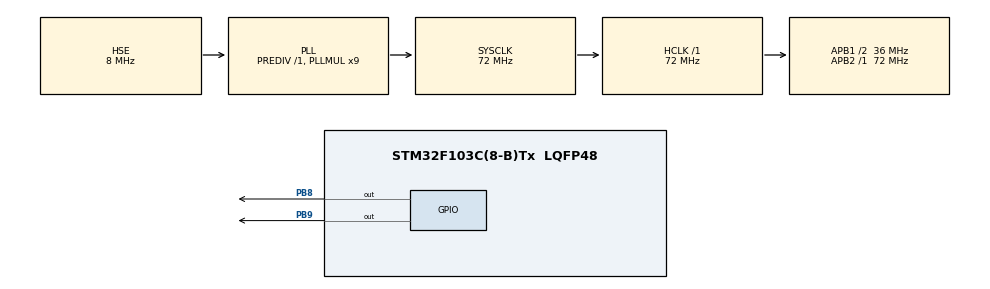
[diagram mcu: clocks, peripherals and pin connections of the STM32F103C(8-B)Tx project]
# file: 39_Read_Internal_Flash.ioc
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Mcu.Family=STM32F1
Mcu.Name=STM32F103C(8-B)Tx
Mcu.Package=LQFP48
NVIC.PriorityGroup=NVIC_PRIORITYGROUP_4
PA13.Mode=Serial_Wire
PA13.Signal=SYS_JTMS-SWDIO
PA14.Mode=Serial_Wire
PA14.Signal=SYS_JTCK-SWCLK
PB8.Signal=GPIO_Output
PB9.Signal=GPIO_Output
PD0-OSC_IN.Mode=HSE-External-Oscillator
PD0-OSC_IN.Signal=RCC_OSC_IN
PD1-OSC_OUT.Mode=HSE-External-Oscillator
PD1-OSC_OUT.Signal=RCC_OSC_OUT
ProjectManager.HeapSize=0x200
ProjectManager.StackSize=0x400
ProjectManager.TargetToolchain=MDK-ARM V5.32
RCC.AHBFreq_Value=72000000
RCC.APB1CLKDivider=RCC_HCLK_DIV2
RCC.APB1Freq_Value=36000000
RCC.APB1TimFreq_Value=72000000
RCC.APB2Freq_Value=72000000
RCC.APB2TimFreq_Value=72000000
RCC.HCLKFreq_Value=72000000
RCC.PLLMUL=RCC_PLL_MUL9
RCC.PLLSourceVirtual=RCC_PLLSOURCE_HSE
RCC.SYSCLKFreq_VALUE=72000000
RCC.SYSCLKSource=RCC_SYSCLKSOURCE_PLLCLK
RCC.USBFreq_Value=72000000
board=custom

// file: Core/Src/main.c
/* USER CODE BEGIN Header */
/**
 ******************************************************************************
 * @file           : main.c
 * @brief          : Main program body
 ******************************************************************************
 * @attention
 *
 * Copyright (c) 2026 STMicroelectronics.
 * All rights reserved.
 *
 * This software is licensed under terms that can be found in the LICENSE file
 * in the root directory of this software component.
 * If no LICENSE file comes with this software, it is provided AS-IS.
 *
 ******************************************************************************
 */
/* USER CODE END Header */
#include "main.h"
#include "gpio.h"

/* USER CODE BEGIN Includes */
#include "OLED.h"
/* USER CODE END Includes */

/* USER CODE BEGIN PV */
/*
  * @brief  FLASH读取一个32位的字(字就是32位)
  * @param  Address: 要读取的地址
  * @retval 指定地址下的数据

*/
uint32_t MyFLASH_ReadWord(uint32_t Address)
{

  /*
  将Address(无符号整数)转换为指针类型
  指定该指针为volatile uint32_t*(即指向32位无符号整数的易变指针)
  通过*运算符解引用该指针，获取该地址下的4字节数据，并返回
  __IO就是volatile的别名，表示该地址的数据可能会被硬件或其他程序修改，所以编译器在优化时会考虑到这一点，不会对该地址的数据进行缓存或优化，以确保每次访问都能获取到最新的数据
  */
  return *(__IO uint32_t *)Address; // 将地址转换为指针，并通过解引用获取该地址下的数据
}

/*
 * @brief  FLASH读取一个16位的半字(半字就是16位)
 * @param  Address: 要读取的地址
 * @retval 指定地址下的数据
 */
uint16_t MyFLASH_ReadHalfWord(uint32_t Address)
{
  return *(__IO uint16_t *)Address; // 将地址转换为指针，并通过解引用获取该地址下的数据
}

/*
  * @brief  FLASH读取一个8位的字节(字节就是8位)
  * @param  Address: 要读取的地址
  * @retval 指定地址下的数据
*/
uint8_t MyFLASH_ReadByte(uint32_t Address)
{
  return *(__IO uint8_t *)Address; // 将地址转换为指针，并通过解引用获取该地址下的数据
}

/* USER CODE END PV */

void SystemClock_Config(void);

int main(void)
{

  /* MCU Configuration--------------------------------------------------------*/

  /* Reset of all peripherals, Initializes the Flash interface and the Systick. */
  HAL_Init();

  /* Configure the system clock */
  SystemClock_Config();

  /* Initialize all configured peripherals */
  MX_GPIO_Init();
  /* USER CODE BEGIN 2 */
  OLED_Init();
  OLED_Clear();

  OLED_ShowHexNum(1 ,1, MyFLASH_ReadWord(0x08000000), 8); // 读取地址0x08000000下的32位数据，并以16进制形式显示在OLED上，显示长度为8个字符
  OLED_ShowHexNum(3 ,1, MyFLASH_ReadHalfWord(0x08000000), 4); // 读取地址0x08000000下的16位数据，并以16进制形式显示在OLED上，显示长度为4个字符
  OLED_ShowHexNum(5 ,1, MyFLASH_ReadByte(0x08000000), 2); // 读取地址0x08000000下的8位数据，并以16进制形式显示在OLED上，显示长度为2个字符

  /* USER CODE END 2 */

  /* Infinite loop */
  while (1)
  {

  }
}

void SystemClock_Config(void)
{
  RCC_OscInitTypeDef RCC_OscInitStruct = {0};
  RCC_ClkInitTypeDef RCC_ClkInitStruct = {0};

  /** Initializes the RCC Oscillators according to the specified parameters
   * in the RCC_OscInitTypeDef structure.
   */
  RCC_OscInitStruct.OscillatorType = RCC_OSCILLATORTYPE_HSE;
  RCC_OscInitStruct.HSEState = RCC_HSE_ON;
  RCC_OscInitStruct.HSEPredivValue = RCC_HSE_PREDIV_DIV1;
  RCC_OscInitStruct.HSIState = RCC_HSI_ON;
  RCC_OscInitStruct.PLL.PLLState = RCC_PLL_ON;
  RCC_OscInitStruct.PLL.PLLSource = RCC_PLLSOURCE_HSE;
  RCC_OscInitStruct.PLL.PLLMUL = RCC_PLL_MUL9;
  if (HAL_RCC_OscConfig(&RCC_OscInitStruct) != HAL_OK)
  {
    Error_Handler();
  }

  /** Initializes the CPU, AHB and APB buses clocks
   */
  RCC_ClkInitStruct.ClockType = RCC_CLOCKTYPE_HCLK | RCC_CLOCKTYPE_SYSCLK | RCC_CLOCKTYPE_PCLK1 | RCC_CLOCKTYPE_PCLK2;
  RCC_ClkInitStruct.SYSCLKSource = RCC_SYSCLKSOURCE_PLLCLK;
  RCC_ClkInitStruct.AHBCLKDivider = RCC_SYSCLK_DIV1;
  RCC_ClkInitStruct.APB1CLKDivider = RCC_HCLK_DIV2;
  RCC_ClkInitStruct.APB2CLKDivider = RCC_HCLK_DIV1;

  if (HAL_RCC_ClockConfig(&RCC_ClkInitStruct, FLASH_LATENCY_2) != HAL_OK)
  {
    Error_Handler();
  }
}

void Error_Handler(void)
{
  __disable_irq();
  while (1)
  {
  }
}
